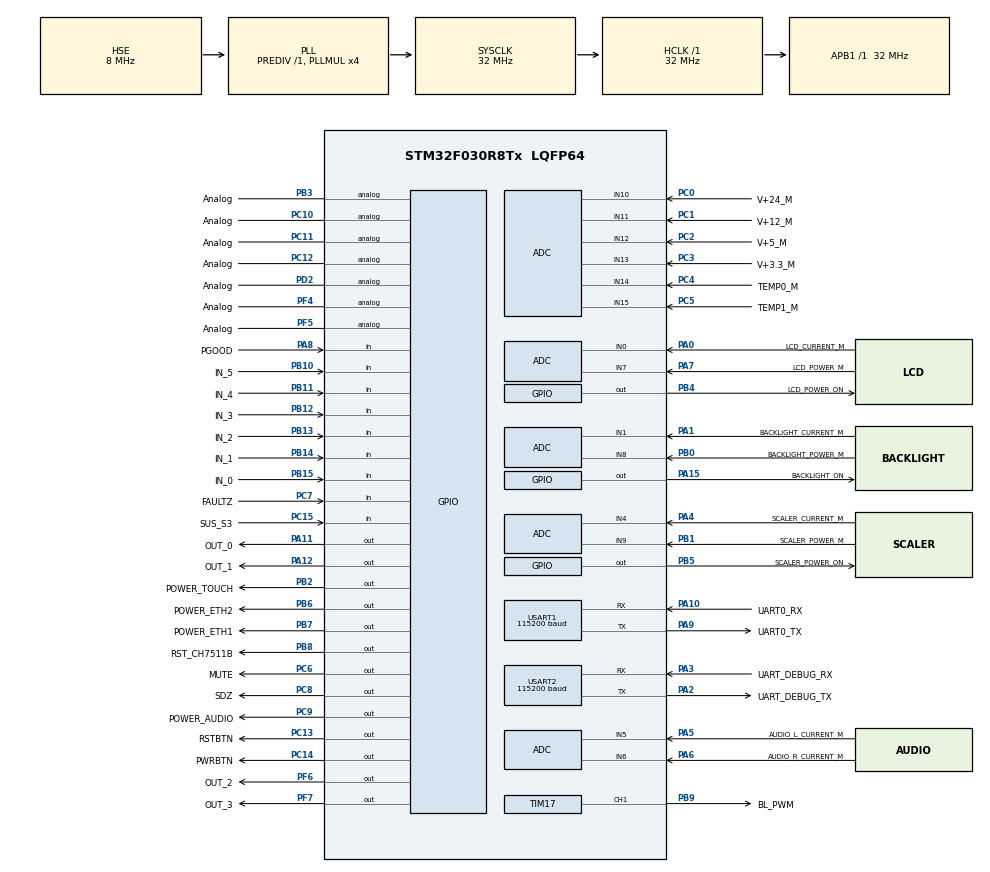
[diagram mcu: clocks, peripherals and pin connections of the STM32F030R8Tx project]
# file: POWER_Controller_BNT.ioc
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ADC.ContinuousConvMode=ENABLE
ADC.DMAContinuousRequests=ENABLE
ADC.EOCSelection=ADC_EOC_SEQ_CONV
ADC.SamplingTime=ADC_SAMPLETIME_239CYCLES_5
Dma.ADC.0.Direction=DMA_PERIPH_TO_MEMORY
Dma.ADC.0.Instance=DMA1_Channel1
Dma.ADC.0.MemDataAlignment=DMA_MDATAALIGN_HALFWORD
Dma.ADC.0.MemInc=DMA_MINC_ENABLE
Dma.ADC.0.Mode=DMA_CIRCULAR
Dma.ADC.0.PeriphDataAlignment=DMA_PDATAALIGN_HALFWORD
Dma.ADC.0.PeriphInc=DMA_PINC_DISABLE
Dma.ADC.0.Priority=DMA_PRIORITY_HIGH
Dma.Request0=ADC
IWDG.Prescaler=IWDG_PRESCALER_256
IWDG.Reload=4095
IWDG.Window=4095
Mcu.Family=STM32F0
Mcu.Name=STM32F030R8Tx
Mcu.Package=LQFP64
NVIC.DMA1_Channel1_IRQn=true\:1\:0\:true\:false\:true\:false\:true\:true
NVIC.USART1_IRQn=true\:2\:0\:true\:false\:true\:true\:true\:true
NVIC.USART2_IRQn=true\:3\:0\:true\:false\:true\:true\:true\:true
PA0.GPIO_Label=LCD_CURRENT_M
PA0.Signal=SharedAnalog_PA0
PA1.GPIO_Label=BACKLIGHT_CURRENT_M
PA1.Signal=SharedAnalog_PA1
PA10.GPIO_Label=UART0_RX
PA10.GPIO_Speed=GPIO_SPEED_FREQ_LOW
PA10.Mode=Asynchronous
PA10.Signal=USART1_RX
PA11.GPIO_Label=OUT_0
PA11.GPIO_ModeDefaultOutputPP=GPIO_MODE_OUTPUT_PP
PA11.Signal=GPIO_Output
PA12.GPIO_Label=OUT_1
PA12.Signal=GPIO_Output
PA13.Mode=Serial_Wire
PA13.Signal=SYS_SWDIO
PA14.Mode=Serial_Wire
PA14.Signal=SYS_SWCLK
PA15.GPIO_Label=BACKLIGHT_ON
PA15.Signal=GPIO_Output
PA2.GPIO_Label=UART_DEBUG_TX
PA2.GPIO_Speed=GPIO_SPEED_FREQ_LOW
PA2.Mode=Asynchronous
PA2.Signal=USART2_TX
PA3.GPIO_Label=UART_DEBUG_RX
PA3.GPIO_Speed=GPIO_SPEED_FREQ_LOW
PA3.Mode=Asynchronous
PA3.Signal=USART2_RX
PA4.GPIO_Label=SCALER_CURRENT_M
PA4.Signal=SharedAnalog_PA4
PA5.GPIO_Label=AUDIO_L_CURRENT_M
PA5.Signal=SharedAnalog_PA5
PA6.GPIO_Label=AUDIO_R_CURRENT_M
PA6.Signal=SharedAnalog_PA6
PA7.GPIO_Label=LCD_POWER_M
PA7.Signal=SharedAnalog_PA7
PA8.GPIO_Label=PGOOD
PA8.Signal=GPIO_Input
PA9.GPIO_Label=UART0_TX
PA9.GPIO_Speed=GPIO_SPEED_FREQ_LOW
PA9.Mode=Asynchronous
PA9.Signal=USART1_TX
PB0.GPIO_Label=BACKLIGHT_POWER_M
PB0.Signal=SharedAnalog_PB0
PB1.GPIO_Label=SCALER_POWER_M
PB1.Signal=SharedAnalog_PB1
PB10.GPIO_Label=IN_5
PB10.Signal=GPIO_Input
PB11.GPIO_Label=IN_4
PB11.Signal=GPIO_Input
PB12.GPIO_Label=IN_3
PB12.Signal=GPIO_Input
PB13.GPIO_Label=IN_2
PB13.Signal=GPIO_Input
PB14.GPIO_Label=IN_1
PB14.Signal=GPIO_Input
PB15.GPIO_Label=IN_0
PB15.Signal=GPIO_Input
PB2.GPIO_Label=POWER_TOUCH
PB2.Signal=GPIO_Output
PB3.GPIO_Label=Analog
PB3.Signal=GPIO_Analog
PB4.GPIO_Label=LCD_POWER_ON
PB4.Signal=GPIO_Output
PB5.GPIO_Label=SCALER_POWER_ON
PB5.Signal=GPIO_Output
PB6.GPIO_Label=POWER_ETH2
PB6.PinState=GPIO_PIN_SET
PB6.Signal=GPIO_Output
PB7.GPIO_Label=POWER_ETH1
PB7.PinState=GPIO_PIN_SET
PB7.Signal=GPIO_Output
PB8.GPIO_Label=RST_CH7511B
PB8.GPIO_ModeDefaultOutputPP=GPIO_MODE_OUTPUT_OD
PB8.GPIO_PuPd=GPIO_NOPULL
PB8.Signal=GPIO_Output
PB9.GPIO_Label=BL_PWM
PB9.Signal=S_TIM17_CH1
PC0.GPIO_Label=V+24_M
PC0.Signal=SharedAnalog_PC0
PC1.GPIO_Label=V+12_M
PC1.Signal=SharedAnalog_PC1
PC10.GPIO_Label=Analog
PC10.Signal=GPIO_Analog
PC11.GPIO_Label=Analog
PC11.Signal=GPIO_Analog
PC12.GPIO_Label=Analog
PC12.Signal=GPIO_Analog
PC13.GPIO_Label=RSTBTN
PC13.GPIO_ModeDefaultOutputPP=GPIO_MODE_OUTPUT_OD
PC13.GPIO_PuPd=GPIO_NOPULL
PC13.PinState=GPIO_PIN_SET
PC13.Signal=GPIO_Output
PC14-OSC32_IN.GPIO_Label=PWRBTN
PC14-OSC32_IN.GPIO_ModeDefaultOutputPP=GPIO_MODE_OUTPUT_OD
PC14-OSC32_IN.GPIO_PuPd=GPIO_NOPULL
PC14-OSC32_IN.PinState=GPIO_PIN_SET
PC14-OSC32_IN.Signal=GPIO_Output
PC15-OSC32_OUT.GPIO_Label=SUS_S3
PC15-OSC32_OUT.Signal=GPIO_Input
PC2.GPIO_Label=V+5_M
PC2.Signal=SharedAnalog_PC2
PC3.GPIO_Label=V+3.3_M
PC3.Signal=SharedAnalog_PC3
PC4.GPIO_Label=TEMP0_M
PC4.Signal=SharedAnalog_PC4
PC5.GPIO_Label=TEMP1_M
PC5.Signal=SharedAnalog_PC5
PC6.GPIO_Label=MUTE
PC6.PinState=GPIO_PIN_SET
PC6.Signal=GPIO_Output
PC7.GPIO_Label=FAULTZ
PC7.Signal=GPIO_Input
PC8.GPIO_Label=SDZ
PC8.Signal=GPIO_Output
PC9.GPIO_Label=POWER_AUDIO
PC9.Signal=GPIO_Output
PD2.GPIO_Label=Analog
PD2.Signal=GPIO_Analog
PF0-OSC_IN.Mode=HSE-External-Oscillator
PF0-OSC_IN.Signal=RCC_OSC_IN
PF1-OSC_OUT.Mode=HSE-External-Oscillator
PF1-OSC_OUT.Signal=RCC_OSC_OUT
PF4.GPIO_Label=Analog
PF4.Signal=GPIO_Analog
PF5.GPIO_Label=Analog
PF5.Signal=GPIO_Analog
PF6.GPIO_Label=OUT_2
PF6.Signal=GPIO_Output
PF7.GPIO_Label=OUT_3
PF7.Signal=GPIO_Output
ProjectManager.HeapSize=0x100
ProjectManager.StackSize=0x600
ProjectManager.TargetToolchain=Makefile
RCC.AHBFreq_Value=32000000
RCC.APB1Freq_Value=32000000
RCC.APB1TimFreq_Value=32000000
RCC.HCLKFreq_Value=32000000
RCC.PLLMUL=RCC_PLL_MUL4
RCC.PLLSourceVirtual=RCC_PLLSOURCE_HSE
RCC.SYSCLKFreq_VALUE=32000000
RCC.SYSCLKSource=RCC_SYSCLKSOURCE_PLLCLK
SH.S_TIM17_CH1.0=TIM17_CH1,PWM Generation1 CH1
SH.SharedAnalog_PA0.0=GPIO_Analog
SH.SharedAnalog_PA0.1=ADC_IN0,IN0
SH.SharedAnalog_PA1.0=GPIO_Analog
SH.SharedAnalog_PA1.1=ADC_IN1,IN1
SH.SharedAnalog_PA4.0=GPIO_Analog
SH.SharedAnalog_PA4.1=ADC_IN4,IN4
SH.SharedAnalog_PA5.0=GPIO_Analog
SH.SharedAnalog_PA5.1=ADC_IN5,IN5
SH.SharedAnalog_PA6.0=GPIO_Analog
SH.SharedAnalog_PA6.1=ADC_IN6,IN6
SH.SharedAnalog_PA7.0=GPIO_Analog
SH.SharedAnalog_PA7.1=ADC_IN7,IN7
SH.SharedAnalog_PB0.0=GPIO_Analog
SH.SharedAnalog_PB0.1=ADC_IN8,IN8
SH.SharedAnalog_PB1.0=GPIO_Analog
SH.SharedAnalog_PB1.1=ADC_IN9,IN9
SH.SharedAnalog_PC0.0=GPIO_Analog
SH.SharedAnalog_PC0.1=ADC_IN10,IN10
SH.SharedAnalog_PC1.0=GPIO_Analog
SH.SharedAnalog_PC1.1=ADC_IN11,IN11
SH.SharedAnalog_PC2.0=GPIO_Analog
SH.SharedAnalog_PC2.1=ADC_IN12,IN12
SH.SharedAnalog_PC3.0=GPIO_Analog
SH.SharedAnalog_PC3.1=ADC_IN13,IN13
SH.SharedAnalog_PC4.0=GPIO_Analog
SH.SharedAnalog_PC4.1=ADC_IN14,IN14
SH.SharedAnalog_PC5.0=GPIO_Analog
SH.SharedAnalog_PC5.1=ADC_IN15,IN15
TIM17.AutoReloadPreload=TIM_AUTORELOAD_PRELOAD_ENABLE
TIM17.Channel=TIM_CHANNEL_1
TIM17.Period=999
TIM17.Prescaler=159
USART1.BaudRate=115200
USART1.VirtualMode-Asynchronous=VM_ASYNC
USART2.BaudRate=115200
USART2.VirtualMode-Asynchronous=VM_ASYNC
VP_IWDG_VS_IWDG.Mode=IWDG_Activate
VP_TIM17_VS_ClockSourceINT.Mode=Enable_Timer
board=custom

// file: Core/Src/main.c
/* USER CODE BEGIN Header */
/**
  ******************************************************************************
  * @file           : main.c
  * @brief          : Main program body
  ******************************************************************************
  * @attention
  *
  * Copyright (c) 2026 STMicroelectronics.
  * All rights reserved.
  *
  * This software is licensed under terms that can be found in the LICENSE file
  * in the root directory of this software component.
  * If no LICENSE file comes with this software, it is provided AS-IS.
  *
  ******************************************************************************
  */
/* USER CODE END Header */
#include "main.h"
#include "adc.h"
#include "dma.h"
#include "iwdg.h"
#include "tim.h"
#include "usart.h"
#include "gpio.h"

/* USER CODE BEGIN Includes */
#include "config.h"
#include "adc_service.h"
#include "input_service.h"
#include "uart_protocol.h"
#include "power_manager.h"
#include "fault_manager.h"
#include "flash_cal.h"
#include "bootloader.h"
#include "app.h"
/* USER CODE END Includes */

void SystemClock_Config(void);

int main(void)
{

  /* USER CODE BEGIN 1 */
  bootloader_check();
  /* Flash remap after ROM Go is done in SystemInit() (before .data/.bss
   * init) — see Core/Src/system_stm32f0xx.c. Too late to do it here. */
  /* USER CODE END 1 */

  /* MCU Configuration--------------------------------------------------------*/

  /* Reset of all peripherals, Initializes the Flash interface and the Systick. */
  HAL_Init();

  /* Configure the system clock */
  SystemClock_Config();

  /* Initialize all configured peripherals */
  MX_GPIO_Init();
  MX_DMA_Init();
  MX_TIM17_Init();  /* before ADC/UART: Error_Handler → power_safe_state uses htim17 */
  MX_ADC_Init();
  MX_USART1_UART_Init();
  MX_USART2_UART_Init();
  MX_IWDG_Init();
  /* USER CODE BEGIN 2 */
  app_init();
  /* USER CODE END 2 */

  /* Infinite loop */
  while (1)
  {

    /* USER CODE BEGIN 3 */
    app_step();
    HAL_IWDG_Refresh(&hiwdg);
  }
  /* USER CODE END 3 */
}

void SystemClock_Config(void)
{
  RCC_OscInitTypeDef RCC_OscInitStruct = {0};
  RCC_ClkInitTypeDef RCC_ClkInitStruct = {0};
  RCC_PeriphCLKInitTypeDef PeriphClkInit = {0};

  /** Initializes the RCC Oscillators according to the specified parameters
  * in the RCC_OscInitTypeDef structure.
  */
  RCC_OscInitStruct.OscillatorType = RCC_OSCILLATORTYPE_HSI14|RCC_OSCILLATORTYPE_LSI
                              |RCC_OSCILLATORTYPE_HSE;
  RCC_OscInitStruct.HSEState = RCC_HSE_ON;
  RCC_OscInitStruct.HSI14State = RCC_HSI14_ON;
  RCC_OscInitStruct.HSI14CalibrationValue = 16;
  RCC_OscInitStruct.LSIState = RCC_LSI_ON;
  RCC_OscInitStruct.PLL.PLLState = RCC_PLL_ON;
  RCC_OscInitStruct.PLL.PLLSource = RCC_PLLSOURCE_HSE;
  RCC_OscInitStruct.PLL.PLLMUL = RCC_PLL_MUL4;
  RCC_OscInitStruct.PLL.PREDIV = RCC_PREDIV_DIV1;
  if (HAL_RCC_OscConfig(&RCC_OscInitStruct) != HAL_OK)
  {
    /* Some F030-compatible clones cannot start with HSE reliably.
     * Fall back to internal HSI to keep firmware operational. */
    RCC_OscInitStruct.OscillatorType = RCC_OSCILLATORTYPE_HSI14|RCC_OSCILLATORTYPE_LSI
                                |RCC_OSCILLATORTYPE_HSI;
    RCC_OscInitStruct.HSEState = RCC_HSE_OFF;
    RCC_OscInitStruct.HSIState = RCC_HSI_ON;
    RCC_OscInitStruct.HSI14State = RCC_HSI14_ON;
    RCC_OscInitStruct.HSI14CalibrationValue = 16;
    RCC_OscInitStruct.LSIState = RCC_LSI_ON;
    RCC_OscInitStruct.PLL.PLLState = RCC_PLL_ON;
    RCC_OscInitStruct.PLL.PLLSource = RCC_PLLSOURCE_HSI;
    RCC_OscInitStruct.PLL.PLLMUL = RCC_PLL_MUL4;
    RCC_OscInitStruct.PLL.PREDIV = RCC_PREDIV_DIV1;
    if (HAL_RCC_OscConfig(&RCC_OscInitStruct) != HAL_OK)
    {
      Error_Handler();
    }
  }

  /** Initializes the CPU, AHB and APB buses clocks
  */
  RCC_ClkInitStruct.ClockType = RCC_CLOCKTYPE_HCLK|RCC_CLOCKTYPE_SYSCLK
                              |RCC_CLOCKTYPE_PCLK1;
  RCC_ClkInitStruct.SYSCLKSource = RCC_SYSCLKSOURCE_PLLCLK;
  RCC_ClkInitStruct.AHBCLKDivider = RCC_SYSCLK_DIV1;
  RCC_ClkInitStruct.APB1CLKDivider = RCC_HCLK_DIV1;

  if (HAL_RCC_ClockConfig(&RCC_ClkInitStruct, FLASH_LATENCY_1) != HAL_OK)
  {
    Error_Handler();
  }
  PeriphClkInit.PeriphClockSelection = RCC_PERIPHCLK_USART1;
  PeriphClkInit.Usart1ClockSelection = RCC_USART1CLKSOURCE_PCLK1;
  if (HAL_RCCEx_PeriphCLKConfig(&PeriphClkInit) != HAL_OK)
  {
    Error_Handler();
  }
}

void Error_Handler(void)
{
  /* USER CODE BEGIN Error_Handler_Debug */
  /* User can add his own implementation to report the HAL error return state */
  __disable_irq();
  fault_set_flag(FAULT_INTERNAL);
  while (1)
  {
  }
  /* USER CODE END Error_Handler_Debug */
}
